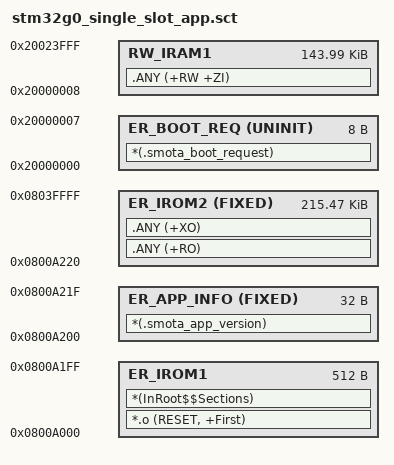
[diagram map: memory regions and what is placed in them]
LR_IROM1 0x0800A000 0x00036000  {
  ER_IROM1 0x0800A000 0x00000200  {
   *.o (RESET, +First)
   *(InRoot$$Sections)
  }
  ER_APP_INFO 0x0800A200 FIXED 0x00000020  {
   *(.smota_app_version)
  }
  ER_IROM2 0x0800A220 FIXED 0x00035DE0  {
   .ANY (+RO)
   .ANY (+XO)
  }
  ER_BOOT_REQ 0x20000000 UNINIT 0x00000008  {
   *(.smota_boot_request)
  }
  RW_IRAM1 0x20000008 0x00023FF8  {
   .ANY (+RW +ZI)
  }
}

